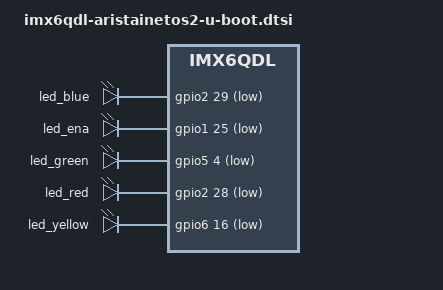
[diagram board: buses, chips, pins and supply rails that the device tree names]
// SPDX-License-Identifier: GPL-2.0+ or X11
/*
 * Copyright (C) 2019 Heiko Schocher <hs@denx.de>
 */

/ {
	leds {
		compatible = "gpio-leds";
		pinctrl-names = "default";
		pinctrl-0 = <&pinctrl_gpio>;

		LED_blue {
			label = "led_blue";
			gpios = <&gpio2 29 GPIO_ACTIVE_LOW>;
		};

		LED_ena {
			label = "led_ena";
			gpios = <&gpio1 25 GPIO_ACTIVE_LOW>;
		};

		LED_green {
			label = "led_green";
			gpios = <&gpio5 4 GPIO_ACTIVE_LOW>;
		};

		LED_red {
			label = "led_red";
			gpios = <&gpio2 28 GPIO_ACTIVE_LOW>;
		};

		LED_yellow {
			label = "led_yellow";
			gpios = <&gpio6 16 GPIO_ACTIVE_LOW>;
		};
	};
};
